# STM32L4R5AGI6 register map
File version: 1.0
Registers are 32-bit, access not given, reset 0x0 unless marked. A register's access mark holds for its fields unless they carry their own. Offsets are from the block's base; [hi:lo] are bit positions; {n}, {i} and the like mark numbered series; 'fields as' and 'values as' point back to an identical list.

## TIM15
Base 0x40014000
0x00 CR1
  [11] UIFREMA, [9:8] CKD, [7] ARPE, [31:4] s, [3] OPM, [2] URS, [1] UDIS, [0] CEN
0x04 CR2
  [10] OIS2, [9] OIS1N, [8] OIS1, [7] TI1S, [6:4] MMS, [3] CCDS, [2] CCUS, [31:1] s, [0] CCPC
0x08 SMCR
  [7] MSM, [6:4] TS, [31:3] s, [16:0] SMS
0x0C DIER
  [14] TDE, [13] COMDE, [9] CC1DE, [8] UDE, [7] BIE, [6] TIE, [5] COMIE, [31:3] s, [2] CC2IE, [1] CC1IE, [0] UIE
0x10 SR
  [10] CC2OF, [9] CC1OF, [7] BIF, [6] TIF, [5] COMIF, [31:3] s, [2] CC2IF, [1] CC1IF, [0] UIF
0x14 EGR
  [7] BG, [6] TG, [5] COMG, [31:3] s, [2] CC2G, [1] CC1G, [0] UG
0x18 CCMR1_OUT
  [24:12] OC2M, [11] OC2PE, [10] OC2FE, [9:8] CC2S, [31:7] s, [16:4] OC1M, [3] OC1PE, [2] OC1FE, [1:0] CC1S
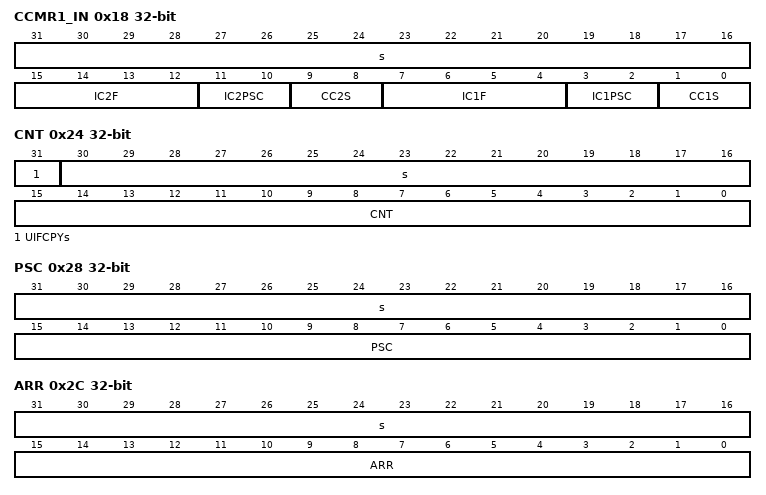
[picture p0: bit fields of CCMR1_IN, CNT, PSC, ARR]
0x18 CCMR1_IN
  [31:16] s, [15:12] IC2F, [11:10] IC2PSC, [9:8] CC2S, [7:4] IC1F, [3:2] IC1PSC, [1:0] CC1S
0x20 CCER
  [7] CC2NP, [31:6] s, [5] CC2P, [4] CC2E, [3] CC1NP, [2] CC1NE, [1] CC1P, [0] CC1E
0x24 CNT
  [31] UIFCPYs, [30:16] s, [15:0] CNT
0x28 PSC
  [31:16] s, [15:0] PSC
0x2C ARR
  [31:16] s, [15:0] ARR
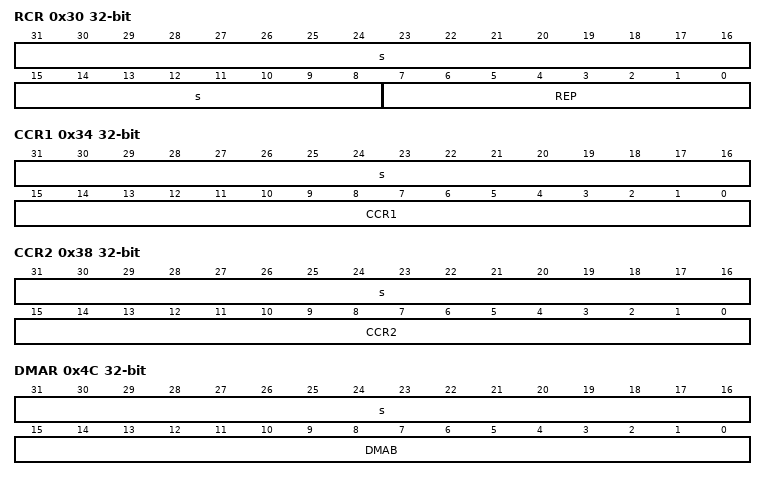
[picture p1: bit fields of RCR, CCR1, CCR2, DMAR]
0x30 RCR
  [31:8] s, [7:0] REP
0x34 CCR1
  [31:16] s, [15:0] CCR1
0x38 CCR2
  [31:16] s, [15:0] CCR2
0x44 BDTR
  [28] BKBID, [26] BKDSRM, [31:16] s, [15] MOE, [14] AOE, [13] BKP, [12] BKE, [11] OSSR, [10] OSSI, [9:8] LOCK, [7:0] DTG
0x48 DCR
  [12:8] DBL, [31:5] s, [4:0] DBA
0x4C DMAR
  [31:16] s, [15:0] DMAB
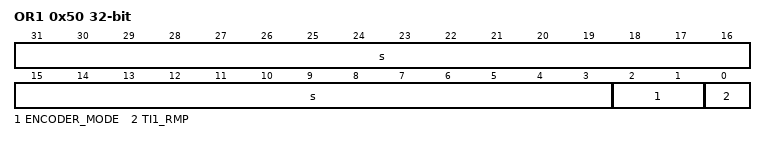
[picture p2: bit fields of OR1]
0x50 OR1
  [31:3] s, [2:1] ENCODER_MODE, [0] TI1_RMP
0x60 OR2
  [11] BKCMP2P, [10] BKCMP1P, [9] BKINP, [8] BKDF1BK0E, [31:3] s, [2] BKCMP2E, [1] BKCMP1E, [0] BKINE

## TIM16
Base 0x40014400
0x00 CR1
  [11] UIFREMA, [9:8] CKD, [7] ARPE, [31:4] s, [3] OPM, [2] URS, [1] UDIS, [0] CEN
0x04 CR2
  [9] OIS1N, [8] OIS1, [3] CCDS, [2] CCUS, [31:1] s, [0] CCPC
0x0C DIER
  [9] CC1DE, [8] UDE, [7] BIE, [5] COMIE, [31:2] s, [1] CC1IE, [0] UIE
0x10 SR
  [9] CC1OF, [7] BIF, [5] COMIF, [31:2] s, [1] CC1IF, [0] UIF
0x14 EGR
  [7] BG, [5] COMG, [31:2] s, [1] CC1G, [0] UG
0x18 CCMR1_OUT
  [31:7] s, [16:4] OC1M, [3] OC1PE, [2] OC1FE, [1:0] CC1S
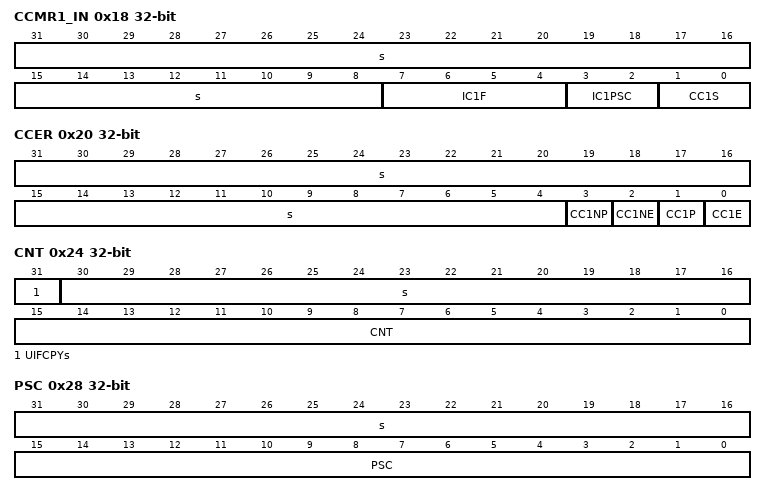
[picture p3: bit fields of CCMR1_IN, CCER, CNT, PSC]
0x18 CCMR1_IN
  [31:8] s, [7:4] IC1F, [3:2] IC1PSC, [1:0] CC1S
0x20 CCER
  [31:4] s, [3] CC1NP, [2] CC1NE, [1] CC1P, [0] CC1E
0x24 CNT
  [31] UIFCPYs, [30:16] s, [15:0] CNT
0x28 PSC
  [31:16] s, [15:0] PSC
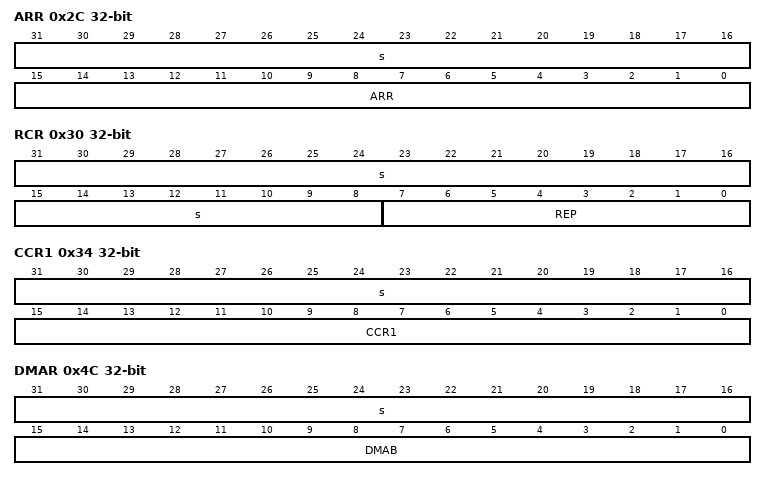
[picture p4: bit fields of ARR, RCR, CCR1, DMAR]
0x2C ARR
  [31:16] s, [15:0] ARR
0x30 RCR
  [31:8] s, [7:0] REP
0x34 CCR1
  [31:16] s, [15:0] CCR1
0x44 BDTR
  [28] BKBID, [26] BKDSRM, [31:16] s, [15] MOE, [14] AOE, [13] BKP, [12] BKE, [11] OSSR, [10] OSSI, [9:8] LOCK, [7:0] DTG
0x48 DCR
  [12:8] DBL, [31:5] s, [4:0] DBA
0x4C DMAR
  [31:16] s, [15:0] DMAB
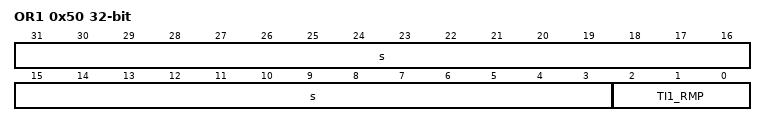
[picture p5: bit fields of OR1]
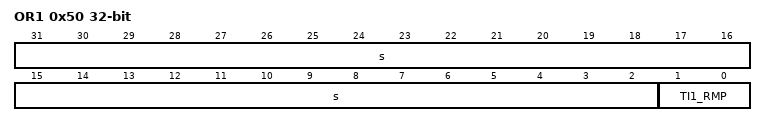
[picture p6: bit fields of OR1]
0x50 OR1
  [31:3] s, [2:0] TI1_RMP
0x60 OR2
  [11] BKCMP2P, [10] BKCMP1P, [9] BKINP, [8] BKDF1BK1E, [31:3] s, [2] BKCMP2E, [1] BKCMP1E, [0] BKINE

## TIM17
Base 0x40014800
Registers as TIM16; these are added or differ:
0x50 OR1
  [31:2] s, [1:0] TI1_RMP
0x60 OR2
  [11] BKCMP2P, [10] BKCMP1P, [9] BKINP, [8] BKDF1BK2E, [31:3] s, [2] BKCMP2E, [1] BKCMP1E, [0] BKINE

## SAI1
Base 0x40015400
Same registers: SAI2 0x40015800
0x00 GCR
  [5:4] SYNCOUT, [31:2] s, [1:0] SYNCIN
0x04 CR1A
  [26] OSR, [25:20] MCKDIV, [19] NOMCK, [17] DMAEN, [16] SAIEN, [13] OUTDRIV, [12] MONO, [11:10] SYNCEN, [9] CKSTR, [8] LSBFIRST, [7:5] DS, [31:4] s, [3:2] PRTCFG, [1:0] MODE
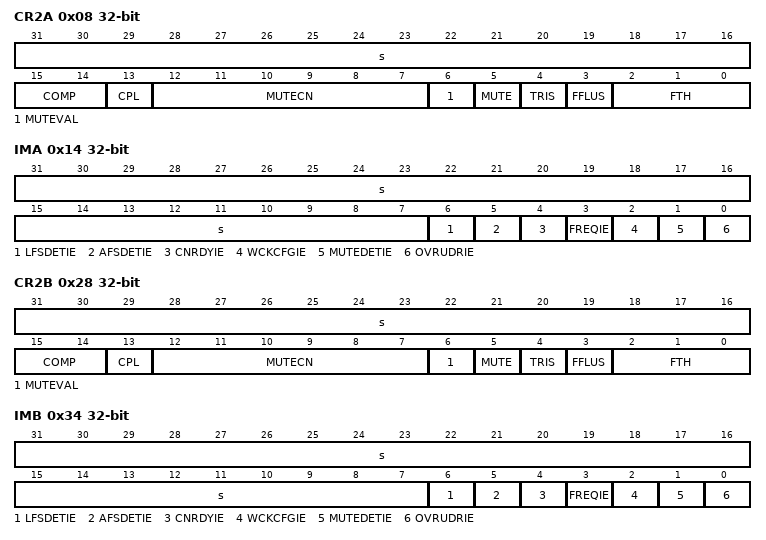
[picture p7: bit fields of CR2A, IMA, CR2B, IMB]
0x08 CR2A
  [31:16] s, [15:14] COMP, [13] CPL, [12:7] MUTECN, [6] MUTEVAL, [5] MUTE, [4] TRIS, [3] FFLUS, [2:0] FTH
0x0C FRCRA
  [18] FSOFF, [17] FSPOL, [16] FSDEF, [31:15] s, [14:8] FSALL, [7:0] FRL
0x10 SLOTRA
  [31:16] SLOTEN, [11:8] NBSLOT, [7:6] SLOTSZ, [15:5] s, [4:0] FBOFF
0x14 IMA
  [31:7] s, [6] LFSDETIE, [5] AFSDETIE, [4] CNRDYIE, [3] FREQIE, [2] WCKCFGIE, [1] MUTEDETIE, [0] OVRUDRIE
0x18 SRA
  [18:16] FLVL, [31:7] s, [6] LFSDET, [5] AFSDET, [4] CNRDY, [3] FREQ, [2] WCKCFG, [1] MUTEDET, [0] OVRUDR
0x1C CLRFRA
  [6] CLFSDET, [5] CAFSDET, [4] CCNRDY, [31:3] s, [2] CWCKCFG, [1] CMUTEDET, [0] COVRUDR
0x20 DRA
  [31:0] DATA
0x24 CR1B
  fields as CR1A
0x28 CR2B
  fields as CR2A
0x2C FRCRB
  fields as FRCRA
0x30 SLOTRB
  [31:16] SLOTEN, [11:8] NBSLOT, [7:6] SLOTSZ, [15:5] s, [4:0] FBOFF
0x34 IMB
  fields as IMA
0x38 SRB
  fields as SRA
0x3C CLRFRB
  fields as CLRFRA
0x40 DRB
  [31:0] DATA
0x44 PDMCR
  [9] CKEN2, [8] CKEN1, [5:4] MICNBR, [31:1] s, [0] PDMEN
0x48 PDMDLY
  [8n-2:8n-4] DLYM{n}R (n=1..4), [8n-6:8n-8] DLYM{n}L (n=1..4), [31:3] s
